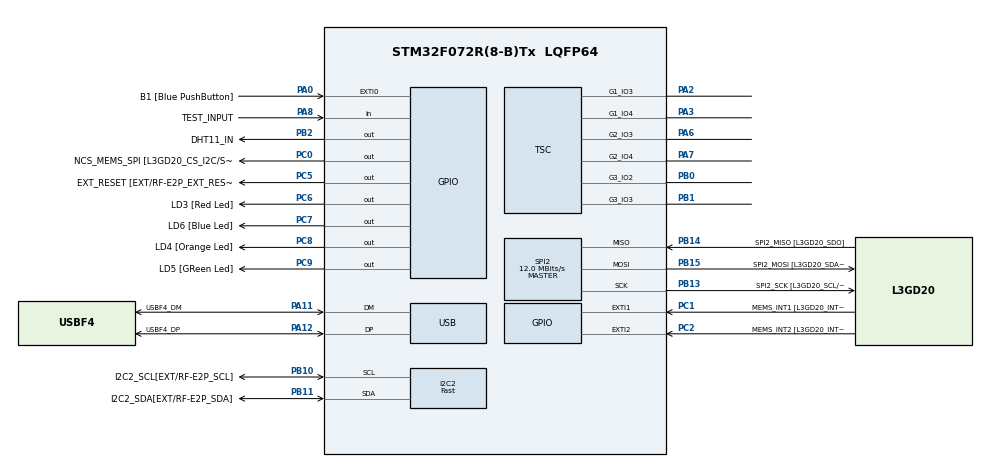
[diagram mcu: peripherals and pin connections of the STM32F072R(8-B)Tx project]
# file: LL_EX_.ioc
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I2C2.I2C_Speed_Mode=I2C_Fast
I2C2.Timing=0x2010091A
Mcu.Family=STM32F0
Mcu.Name=STM32F072R(8-B)Tx
Mcu.Package=LQFP64
NVIC.TIM6_DAC_IRQn=true\:0\:0\:false\:false\:true\:true\:true
PA0.GPIO_Label=B1 [Blue PushButton]
PA0.GPIO_ModeDefaultEXTI=GPIO_MODE_EVT_RISING
PA0.Signal=GPXTI0
PA11.GPIO_Label=USBF4_DM
PA11.Mode=Device
PA11.Signal=USB_DM
PA12.GPIO_Label=USBF4_DP
PA12.Mode=Device
PA12.Signal=USB_DP
PA13.GPIO_Label=SWDIO
PA13.Mode=Serial_Wire
PA13.Signal=SYS_SWDIO
PA14.GPIO_Label=SWCLK
PA14.Mode=Serial_Wire
PA14.Signal=SYS_SWCLK
PA2.Mode=G1_IO3-Channel
PA2.Signal=TSC_G1_IO3
PA3.Mode=G1_IO4-Sampling
PA3.Signal=TSC_G1_IO4
PA6.Mode=G2_IO3-Channel
PA6.Signal=TSC_G2_IO3
PA7.Mode=G2_IO4-Sampling
PA7.Signal=TSC_G2_IO4
PA8.GPIO_Label=TEST_INPUT
PA8.Signal=GPIO_Input
PB0.Mode=G3_IO2-Channel
PB0.Signal=TSC_G3_IO2
PB1.Mode=G3_IO3-Sampling
PB1.Signal=TSC_G3_IO3
PB10.GPIO_Label=I2C2_SCL[EXT/RF-E2P_SCL]
PB10.GPIO_Pu=GPIO_PULLUP
PB10.Mode=I2C
PB10.Signal=I2C2_SCL
PB11.GPIO_Label=I2C2_SDA[EXT/RF-E2P_SDA]
PB11.GPIO_Pu=GPIO_PULLUP
PB11.Mode=I2C
PB11.Signal=I2C2_SDA
PB13.GPIO_Label=SPI2_SCK [L3GD20_SCL/SPC]
PB13.Mode=Full_Duplex_Master
PB13.Signal=SPI2_SCK
PB14.GPIO_Label=SPI2_MISO [L3GD20_SDO]
PB14.Mode=Full_Duplex_Master
PB14.Signal=SPI2_MISO
PB15.GPIO_Label=SPI2_MOSI [L3GD20_SDA/SDI]
PB15.Mode=Full_Duplex_Master
PB15.Signal=SPI2_MOSI
PB2.GPIO_Label=DHT11_IN
PB2.GPIO_PuPd=GPIO_PULLUP
PB2.GPIO_Speed=GPIO_SPEED_FREQ_LOW
PB2.Signal=GPIO_Output
PC0.GPIO_Label=NCS_MEMS_SPI [L3GD20_CS_I2C/SPI]
PC0.Signal=GPIO_Output
PC1.GPIO_Label=MEMS_INT1 [L3GD20_INT1]
PC1.GPIO_ModeDefaultEXTI=GPIO_MODE_EVT_RISING
PC1.Signal=GPXTI1
PC2.GPIO_Label=MEMS_INT2 [L3GD20_INT2]
PC2.GPIO_ModeDefaultEXTI=GPIO_MODE_EVT_RISING
PC2.Signal=GPXTI2
PC5.GPIO_Label=EXT_RESET [EXT/RF-E2P_EXT_RESET]
PC5.Signal=GPIO_Output
PC6.GPIO_Label=LD3 [Red Led]
PC6.Signal=GPIO_Output
PC7.GPIO_Label=LD6 [Blue Led]
PC7.Signal=GPIO_Output
PC8.GPIO_Label=LD4 [Orange Led]
PC8.Signal=GPIO_Output
PC9.GPIO_Label=LD5 [GReen Led]
PC9.Signal=GPIO_Output
ProjectManager.HeapSize=0x200
ProjectManager.StackSize=0x400
ProjectManager.TargetToolchain=STM32CubeIDE
RCC.AHBFreq_Value=48000000
RCC.APB1Freq_Value=48000000
RCC.APB1TimFreq_Value=48000000
RCC.HCLKFreq_Value=48000000
RCC.PLLMUL=RCC_PLL_MUL6
RCC.SYSCLKFreq_VALUE=48000000
RCC.SYSCLKSource=RCC_SYSCLKSOURCE_PLLCLK
SPI2.BaudRatePrescaler=SPI_BAUDRATEPRESCALER_4
SPI2.CalculateBaudRate=12.0 MBits/s
SPI2.Direction=SPI_DIRECTION_2LINES
SPI2.Mode=SPI_MODE_MASTER
SPI2.VirtualType=VM_MASTER
TIM6.Period=0xffff-1
TIM6.Prescaler=47
USB.phy_itface=PCD_PHY_EMBEDDED
USB.speed=PCD_SPEED_FULL
VP_TIM6_VS_ClockSourceINT.Mode=Enable_Timer
board=STM32F072B-DISCO

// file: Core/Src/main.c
/* USER CODE BEGIN Header */
/**
  ******************************************************************************
  * @file           : main.c
  * @brief          : Main program body
  ******************************************************************************
  * @attention
  *
  * <h2><center>&copy; Copyright (c) 2021 STMicroelectronics.
  * All rights reserved.</center></h2>
  *
  * This software component is licensed by ST under BSD 3-Clause license,
  * the "License"; You may not use this file except in compliance with the
  * License. You may obtain a copy of the License at:
  *                        opensource.org/licenses/BSD-3-Clause
  *
  ******************************************************************************
  */
/* USER CODE END Header */
#include "main.h"

/* USER CODE BEGIN Includes */
#include "BSL.h"
/* USER CODE END Includes */

TSC_HandleTypeDef htsc;

PCD_HandleTypeDef hpcd_USB_FS;

void SystemClock_Config(void);
static void MX_GPIO_Init(void);
static void MX_SPI2_Init(void);
static void MX_TSC_Init(void);
static void MX_USB_PCD_Init(void);
static void MX_TIM6_Init(void);

int main(void)
{

  /* MCU Configuration--------------------------------------------------------*/

  /* Reset of all peripherals, Initializes the Flash interface and the Systick. */
  HAL_Init();

  /* Configure the system clock */
  SystemClock_Config();

  /* Initialize all configured peripherals */
  MX_GPIO_Init();
  MX_I2C2_Init();
  MX_SPI2_Init();
  MX_TSC_Init();
  MX_USB_PCD_Init();
  MX_TIM6_Init();
  /* USER CODE BEGIN 2 */
  BSL_Startup();

  BSL_Config();

  BSL_Control();
  /* USER CODE END 2 */

  /* Infinite loop */
  while (1)
  {

  }
}

void SystemClock_Config(void)
{
  LL_FLASH_SetLatency(LL_FLASH_LATENCY_1);
  while(LL_FLASH_GetLatency() != LL_FLASH_LATENCY_1)
  {
  }
  LL_RCC_HSI_Enable();

   /* Wait till HSI is ready */
  while(LL_RCC_HSI_IsReady() != 1)
  {

  }
  LL_RCC_HSI_SetCalibTrimming(16);
  LL_RCC_HSI48_Enable();

   /* Wait till HSI48 is ready */
  while(LL_RCC_HSI48_IsReady() != 1)
  {

  }
  LL_RCC_PLL_ConfigDomain_SYS(LL_RCC_PLLSOURCE_HSI, LL_RCC_PLL_MUL_6, LL_RCC_PREDIV_DIV_1);
  LL_RCC_PLL_Enable();

   /* Wait till PLL is ready */
  while(LL_RCC_PLL_IsReady() != 1)
  {

  }
  LL_RCC_SetAHBPrescaler(LL_RCC_SYSCLK_DIV_1);
  LL_RCC_SetAPB1Prescaler(LL_RCC_APB1_DIV_1);
  LL_RCC_SetSysClkSource(LL_RCC_SYS_CLKSOURCE_PLL);

   /* Wait till System clock is ready */
  while(LL_RCC_GetSysClkSource() != LL_RCC_SYS_CLKSOURCE_STATUS_PLL)
  {

  }
  LL_SetSystemCoreClock(48000000);

   /* Update the time base */
  if (HAL_InitTick (TICK_INT_PRIORITY) != HAL_OK)
  {
    Error_Handler();
  }
  LL_RCC_SetUSBClockSource(LL_RCC_USB_CLKSOURCE_HSI48);
}

void MX_I2C2_Init(void)
{

  LL_I2C_InitTypeDef I2C_InitStruct = {0};

  LL_GPIO_InitTypeDef GPIO_InitStruct = {0};

  LL_AHB1_GRP1_EnableClock(LL_AHB1_GRP1_PERIPH_GPIOB);
  /**I2C2 GPIO Configuration
  PB10   ------> I2C2_SCL
  PB11   ------> I2C2_SDA
  */
  GPIO_InitStruct.Pin = I2C2_SCL_Pin;
  GPIO_InitStruct.Mode = LL_GPIO_MODE_ALTERNATE;
  GPIO_InitStruct.Speed = LL_GPIO_SPEED_FREQ_HIGH;
  GPIO_InitStruct.OutputType = LL_GPIO_OUTPUT_OPENDRAIN;
  GPIO_InitStruct.Pull = LL_GPIO_PULL_UP;
  GPIO_InitStruct.Alternate = LL_GPIO_AF_1;
  LL_GPIO_Init(I2C2_SCL_GPIO_Port, &GPIO_InitStruct);

  GPIO_InitStruct.Pin = I2C2_SDA_Pin;
  GPIO_InitStruct.Mode = LL_GPIO_MODE_ALTERNATE;
  GPIO_InitStruct.Speed = LL_GPIO_SPEED_FREQ_HIGH;
  GPIO_InitStruct.OutputType = LL_GPIO_OUTPUT_OPENDRAIN;
  GPIO_InitStruct.Pull = LL_GPIO_PULL_UP;
  GPIO_InitStruct.Alternate = LL_GPIO_AF_1;
  LL_GPIO_Init(I2C2_SDA_GPIO_Port, &GPIO_InitStruct);

  /* Peripheral clock enable */
  LL_APB1_GRP1_EnableClock(LL_APB1_GRP1_PERIPH_I2C2);

  /** I2C Initialization
  */
  LL_I2C_DisableOwnAddress2(I2C2);
  LL_I2C_DisableGeneralCall(I2C2);
  LL_I2C_EnableClockStretching(I2C2);
  I2C_InitStruct.PeripheralMode = LL_I2C_MODE_I2C;
  I2C_InitStruct.Timing = 0x2010091A;
  I2C_InitStruct.AnalogFilter = LL_I2C_ANALOGFILTER_ENABLE;
  I2C_InitStruct.DigitalFilter = 0;
  I2C_InitStruct.OwnAddress1 = 0;
  I2C_InitStruct.TypeAcknowledge = LL_I2C_ACK;
  I2C_InitStruct.OwnAddrSize = LL_I2C_OWNADDRESS1_7BIT;
  LL_I2C_Init(I2C2, &I2C_InitStruct);
  LL_I2C_EnableAutoEndMode(I2C2);
  LL_I2C_SetOwnAddress2(I2C2, 0, LL_I2C_OWNADDRESS2_NOMASK);

}

static void MX_SPI2_Init(void)
{

  LL_SPI_InitTypeDef SPI_InitStruct = {0};

  LL_GPIO_InitTypeDef GPIO_InitStruct = {0};

  /* Peripheral clock enable */
  LL_APB1_GRP1_EnableClock(LL_APB1_GRP1_PERIPH_SPI2);

  LL_AHB1_GRP1_EnableClock(LL_AHB1_GRP1_PERIPH_GPIOB);
  /**SPI2 GPIO Configuration
  PB13   ------> SPI2_SCK
  PB14   ------> SPI2_MISO
  PB15   ------> SPI2_MOSI
  */
  GPIO_InitStruct.Pin = SPI2_SCK_Pin;
  GPIO_InitStruct.Mode = LL_GPIO_MODE_ALTERNATE;
  GPIO_InitStruct.Speed = LL_GPIO_SPEED_FREQ_HIGH;
  GPIO_InitStruct.OutputType = LL_GPIO_OUTPUT_PUSHPULL;
  GPIO_InitStruct.Pull = LL_GPIO_PULL_NO;
  GPIO_InitStruct.Alternate = LL_GPIO_AF_0;
  LL_GPIO_Init(SPI2_SCK_GPIO_Port, &GPIO_InitStruct);

  GPIO_InitStruct.Pin = SPI2_MISO_Pin;
  GPIO_InitStruct.Mode = LL_GPIO_MODE_ALTERNATE;
  GPIO_InitStruct.Speed = LL_GPIO_SPEED_FREQ_HIGH;
  GPIO_InitStruct.OutputType = LL_GPIO_OUTPUT_PUSHPULL;
  GPIO_InitStruct.Pull = LL_GPIO_PULL_NO;
  GPIO_InitStruct.Alternate = LL_GPIO_AF_0;
  LL_GPIO_Init(SPI2_MISO_GPIO_Port, &GPIO_InitStruct);

  GPIO_InitStruct.Pin = SPI2_MOSI_Pin;
  GPIO_InitStruct.Mode = LL_GPIO_MODE_ALTERNATE;
  GPIO_InitStruct.Speed = LL_GPIO_SPEED_FREQ_HIGH;
  GPIO_InitStruct.OutputType = LL_GPIO_OUTPUT_PUSHPULL;
  GPIO_InitStruct.Pull = LL_GPIO_PULL_NO;
  GPIO_InitStruct.Alternate = LL_GPIO_AF_0;
  LL_GPIO_Init(SPI2_MOSI_GPIO_Port, &GPIO_InitStruct);

  /* SPI2 parameter configuration*/
  SPI_InitStruct.TransferDirection = LL_SPI_FULL_DUPLEX;
  SPI_InitStruct.Mode = LL_SPI_MODE_MASTER;
  SPI_InitStruct.DataWidth = LL_SPI_DATAWIDTH_4BIT;
  SPI_InitStruct.ClockPolarity = LL_SPI_POLARITY_LOW;
  SPI_InitStruct.ClockPhase = LL_SPI_PHASE_1EDGE;
  SPI_InitStruct.NSS = LL_SPI_NSS_SOFT;
  SPI_InitStruct.BaudRate = LL_SPI_BAUDRATEPRESCALER_DIV4;
  SPI_InitStruct.BitOrder = LL_SPI_MSB_FIRST;
  SPI_InitStruct.CRCCalculation = LL_SPI_CRCCALCULATION_DISABLE;
  SPI_InitStruct.CRCPoly = 7;
  LL_SPI_Init(SPI2, &SPI_InitStruct);
  LL_SPI_SetStandard(SPI2, LL_SPI_PROTOCOL_MOTOROLA);
  LL_SPI_EnableNSSPulseMgt(SPI2);

}

static void MX_TIM6_Init(void)
{

  LL_TIM_InitTypeDef TIM_InitStruct = {0};

  /* Peripheral clock enable */
  LL_APB1_GRP1_EnableClock(LL_APB1_GRP1_PERIPH_TIM6);

  /* TIM6 interrupt Init */
  NVIC_SetPriority(TIM6_DAC_IRQn, 0);
  NVIC_EnableIRQ(TIM6_DAC_IRQn);

  TIM_InitStruct.Prescaler = 47;
  TIM_InitStruct.CounterMode = LL_TIM_COUNTERMODE_UP;
  TIM_InitStruct.Autoreload = 0xffff-LL_TIM_IC_FILTER_FDIV1_N2;
  LL_TIM_Init(TIM6, &TIM_InitStruct);
  LL_TIM_DisableARRPreload(TIM6);
  LL_TIM_SetTriggerOutput(TIM6, LL_TIM_TRGO_RESET);
  LL_TIM_DisableMasterSlaveMode(TIM6);
  /* USER CODE BEGIN TIM6_Init 2 */
  LL_TIM_EnableIT_UPDATE(TIM6);
  /* USER CODE END TIM6_Init 2 */

}

static void MX_TSC_Init(void)
{

  /** Configure the TSC peripheral
  */
  htsc.Instance = TSC;
  htsc.Init.CTPulseHighLength = TSC_CTPH_2CYCLES;
  htsc.Init.CTPulseLowLength = TSC_CTPL_2CYCLES;
  htsc.Init.SpreadSpectrum = DISABLE;
  htsc.Init.SpreadSpectrumDeviation = 1;
  htsc.Init.SpreadSpectrumPrescaler = TSC_SS_PRESC_DIV1;
  htsc.Init.PulseGeneratorPrescaler = TSC_PG_PRESC_DIV4;
  htsc.Init.MaxCountValue = TSC_MCV_8191;
  htsc.Init.IODefaultMode = TSC_IODEF_OUT_PP_LOW;
  htsc.Init.SynchroPinPolarity = TSC_SYNC_POLARITY_FALLING;
  htsc.Init.AcquisitionMode = TSC_ACQ_MODE_NORMAL;
  htsc.Init.MaxCountInterrupt = DISABLE;
  htsc.Init.ChannelIOs = TSC_GROUP1_IO3|TSC_GROUP2_IO3|TSC_GROUP3_IO2;
  htsc.Init.ShieldIOs = 0;
  htsc.Init.SamplingIOs = TSC_GROUP1_IO4|TSC_GROUP2_IO4|TSC_GROUP3_IO3;
  if (HAL_TSC_Init(&htsc) != HAL_OK)
  {
    Error_Handler();
  }

}

static void MX_USB_PCD_Init(void)
{

  hpcd_USB_FS.Instance = USB;
  hpcd_USB_FS.Init.dev_endpoints = 8;
  hpcd_USB_FS.Init.speed = PCD_SPEED_FULL;
  hpcd_USB_FS.Init.phy_itface = PCD_PHY_EMBEDDED;
  hpcd_USB_FS.Init.low_power_enable = DISABLE;
  hpcd_USB_FS.Init.lpm_enable = DISABLE;
  hpcd_USB_FS.Init.battery_charging_enable = DISABLE;
  if (HAL_PCD_Init(&hpcd_USB_FS) != HAL_OK)
  {
    Error_Handler();
  }

}

static void MX_GPIO_Init(void)
{
  LL_EXTI_InitTypeDef EXTI_InitStruct = {0};
  LL_GPIO_InitTypeDef GPIO_InitStruct = {0};

  /* GPIO Ports Clock Enable */
  LL_AHB1_GRP1_EnableClock(LL_AHB1_GRP1_PERIPH_GPIOC);
  LL_AHB1_GRP1_EnableClock(LL_AHB1_GRP1_PERIPH_GPIOA);
  LL_AHB1_GRP1_EnableClock(LL_AHB1_GRP1_PERIPH_GPIOB);

  /**/
  LL_GPIO_ResetOutputPin(NCS_MEMS_SPI_GPIO_Port, NCS_MEMS_SPI_Pin);

  /**/
  LL_GPIO_ResetOutputPin(EXT_RESET_GPIO_Port, EXT_RESET_Pin);

  /**/
  LL_GPIO_ResetOutputPin(DHT11_IN_GPIO_Port, DHT11_IN_Pin);

  /**/
  LL_GPIO_ResetOutputPin(LD3_GPIO_Port, LD3_Pin);

  /**/
  LL_GPIO_ResetOutputPin(LD6_GPIO_Port, LD6_Pin);

  /**/
  LL_GPIO_ResetOutputPin(LD4_GPIO_Port, LD4_Pin);

  /**/
  LL_GPIO_ResetOutputPin(LD5_GPIO_Port, LD5_Pin);

  /**/
  GPIO_InitStruct.Pin = NCS_MEMS_SPI_Pin;
  GPIO_InitStruct.Mode = LL_GPIO_MODE_OUTPUT;
  GPIO_InitStruct.Speed = LL_GPIO_SPEED_FREQ_LOW;
  GPIO_InitStruct.OutputType = LL_GPIO_OUTPUT_PUSHPULL;
  GPIO_InitStruct.Pull = LL_GPIO_PULL_NO;
  LL_GPIO_Init(NCS_MEMS_SPI_GPIO_Port, &GPIO_InitStruct);

  /**/
  GPIO_InitStruct.Pin = EXT_RESET_Pin;
  GPIO_InitStruct.Mode = LL_GPIO_MODE_OUTPUT;
  GPIO_InitStruct.Speed = LL_GPIO_SPEED_FREQ_LOW;
  GPIO_InitStruct.OutputType = LL_GPIO_OUTPUT_PUSHPULL;
  GPIO_InitStruct.Pull = LL_GPIO_PULL_NO;
  LL_GPIO_Init(EXT_RESET_GPIO_Port, &GPIO_InitStruct);

  /**/
  GPIO_InitStruct.Pin = DHT11_IN_Pin;
  GPIO_InitStruct.Mode = LL_GPIO_MODE_OUTPUT;
  GPIO_InitStruct.Speed = LL_GPIO_SPEED_FREQ_LOW;
  GPIO_InitStruct.OutputType = LL_GPIO_OUTPUT_PUSHPULL;
  GPIO_InitStruct.Pull = LL_GPIO_PULL_UP;
  LL_GPIO_Init(DHT11_IN_GPIO_Port, &GPIO_InitStruct);

  /**/
  GPIO_InitStruct.Pin = LD3_Pin;
  GPIO_InitStruct.Mode = LL_GPIO_MODE_OUTPUT;
  GPIO_InitStruct.Speed = LL_GPIO_SPEED_FREQ_LOW;
  GPIO_InitStruct.OutputType = LL_GPIO_OUTPUT_PUSHPULL;
  GPIO_InitStruct.Pull = LL_GPIO_PULL_NO;
  LL_GPIO_Init(LD3_GPIO_Port, &GPIO_InitStruct);

  /**/
  GPIO_InitStruct.Pin = LD6_Pin;
  GPIO_InitStruct.Mode = LL_GPIO_MODE_OUTPUT;
  GPIO_InitStruct.Speed = LL_GPIO_SPEED_FREQ_LOW;
  GPIO_InitStruct.OutputType = LL_GPIO_OUTPUT_PUSHPULL;
  GPIO_InitStruct.Pull = LL_GPIO_PULL_NO;
  LL_GPIO_Init(LD6_GPIO_Port, &GPIO_InitStruct);

  /**/
  GPIO_InitStruct.Pin = LD4_Pin;
  GPIO_InitStruct.Mode = LL_GPIO_MODE_OUTPUT;
  GPIO_InitStruct.Speed = LL_GPIO_SPEED_FREQ_LOW;
  GPIO_InitStruct.OutputType = LL_GPIO_OUTPUT_PUSHPULL;
  GPIO_InitStruct.Pull = LL_GPIO_PULL_NO;
  LL_GPIO_Init(LD4_GPIO_Port, &GPIO_InitStruct);

  /**/
  GPIO_InitStruct.Pin = LD5_Pin;
  GPIO_InitStruct.Mode = LL_GPIO_MODE_OUTPUT;
  GPIO_InitStruct.Speed = LL_GPIO_SPEED_FREQ_LOW;
  GPIO_InitStruct.OutputType = LL_GPIO_OUTPUT_PUSHPULL;
  GPIO_InitStruct.Pull = LL_GPIO_PULL_NO;
  LL_GPIO_Init(LD5_GPIO_Port, &GPIO_InitStruct);

  /**/
  GPIO_InitStruct.Pin = TEST_INPUT_Pin;
  GPIO_InitStruct.Mode = LL_GPIO_MODE_INPUT;
  GPIO_InitStruct.Pull = LL_GPIO_PULL_NO;
  LL_GPIO_Init(TEST_INPUT_GPIO_Port, &GPIO_InitStruct);

  /**/
  LL_SYSCFG_SetEXTISource(LL_SYSCFG_EXTI_PORTC, LL_SYSCFG_EXTI_LINE1);

  /**/
  LL_SYSCFG_SetEXTISource(LL_SYSCFG_EXTI_PORTC, LL_SYSCFG_EXTI_LINE2);

  /**/
  LL_SYSCFG_SetEXTISource(LL_SYSCFG_EXTI_PORTA, LL_SYSCFG_EXTI_LINE0);

  /**/
  LL_GPIO_SetPinPull(MEMS_INT1_GPIO_Port, MEMS_INT1_Pin, LL_GPIO_PULL_NO);

  /**/
  LL_GPIO_SetPinPull(MEMS_INT2_GPIO_Port, MEMS_INT2_Pin, LL_GPIO_PULL_NO);

  /**/
  LL_GPIO_SetPinPull(B1_GPIO_Port, B1_Pin, LL_GPIO_PULL_NO);

  /**/
  LL_GPIO_SetPinMode(MEMS_INT1_GPIO_Port, MEMS_INT1_Pin, LL_GPIO_MODE_INPUT);

  /**/
  LL_GPIO_SetPinMode(MEMS_INT2_GPIO_Port, MEMS_INT2_Pin, LL_GPIO_MODE_INPUT);

  /**/
  LL_GPIO_SetPinMode(B1_GPIO_Port, B1_Pin, LL_GPIO_MODE_INPUT);

  /**/
  EXTI_InitStruct.Line_0_31 = LL_EXTI_LINE_1;
  EXTI_InitStruct.LineCommand = ENABLE;
  EXTI_InitStruct.Mode = LL_EXTI_MODE_EVENT;
  EXTI_InitStruct.Trigger = LL_EXTI_TRIGGER_RISING;
  LL_EXTI_Init(&EXTI_InitStruct);

  /**/
  EXTI_InitStruct.Line_0_31 = LL_EXTI_LINE_2;
  EXTI_InitStruct.LineCommand = ENABLE;
  EXTI_InitStruct.Mode = LL_EXTI_MODE_EVENT;
  EXTI_InitStruct.Trigger = LL_EXTI_TRIGGER_RISING;
  LL_EXTI_Init(&EXTI_InitStruct);

  /**/
  EXTI_InitStruct.Line_0_31 = LL_EXTI_LINE_0;
  EXTI_InitStruct.LineCommand = ENABLE;
  EXTI_InitStruct.Mode = LL_EXTI_MODE_EVENT;
  EXTI_InitStruct.Trigger = LL_EXTI_TRIGGER_RISING;
  LL_EXTI_Init(&EXTI_InitStruct);

}

void Error_Handler(void)
{
  __disable_irq();
  while (1)
  {
  }
}

/************************ (C) COPYRIGHT STMicroelectronics *****END OF FILE****/
